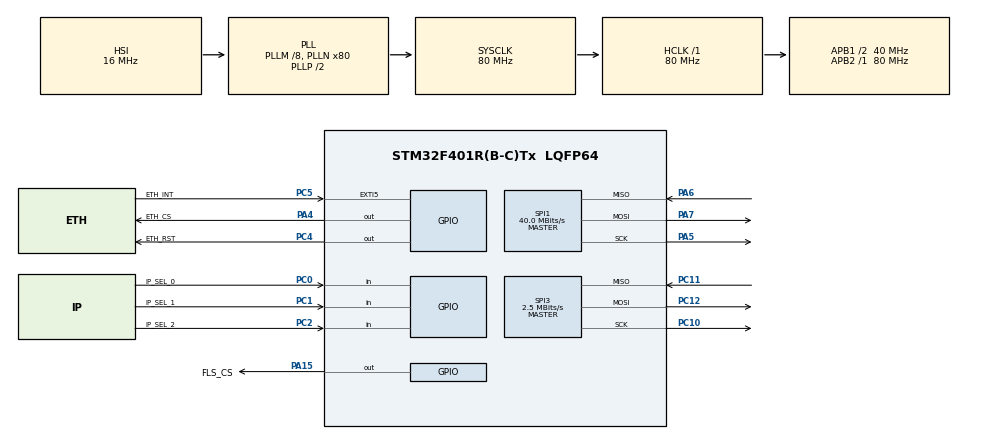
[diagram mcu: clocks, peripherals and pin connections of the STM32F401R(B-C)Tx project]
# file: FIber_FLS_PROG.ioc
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Mcu.Family=STM32F4
Mcu.Name=STM32F401R(B-C)Tx
Mcu.Package=LQFP64
NVIC.EXTI9_5_IRQn=true\:0\:0\:false\:false\:true\:true\:true\:true
NVIC.PriorityGroup=NVIC_PRIORITYGROUP_4
NVIC.SPI1_IRQn=true\:0\:0\:false\:false\:true\:true\:true\:true
NVIC.SPI3_IRQn=true\:0\:0\:false\:false\:true\:true\:true\:true
PA15.GPIO_Label=FLS_CS
PA15.GPIO_PuPd=GPIO_PULLUP
PA15.GPIO_Speed=GPIO_SPEED_FREQ_VERY_HIGH
PA15.PinState=GPIO_PIN_SET
PA15.Signal=GPIO_Output
PA4.GPIO_Label=ETH_CS
PA4.GPIO_ModeDefaultOutputPP=GPIO_MODE_OUTPUT_PP
PA4.GPIO_PuPd=GPIO_PULLUP
PA4.GPIO_Speed=GPIO_SPEED_FREQ_VERY_HIGH
PA4.PinState=GPIO_PIN_SET
PA4.Signal=GPIO_Output
PA5.Mode=Full_Duplex_Master
PA5.Signal=SPI1_SCK
PA6.Mode=Full_Duplex_Master
PA6.Signal=SPI1_MISO
PA7.Mode=Full_Duplex_Master
PA7.Signal=SPI1_MOSI
PC0.GPIO_Label=IP_SEL_0
PC0.Signal=GPIO_Input
PC1.GPIO_Label=IP_SEL_1
PC1.Signal=GPIO_Input
PC10.Mode=Full_Duplex_Master
PC10.Signal=SPI3_SCK
PC11.Mode=Full_Duplex_Master
PC11.Signal=SPI3_MISO
PC12.Mode=Full_Duplex_Master
PC12.Signal=SPI3_MOSI
PC2.GPIO_Label=IP_SEL_2
PC2.Signal=GPIO_Input
PC4.GPIO_Label=ETH_RST
PC4.GPIO_PuPd=GPIO_PULLUP
PC4.GPIO_Speed=GPIO_SPEED_FREQ_HIGH
PC4.PinState=GPIO_PIN_SET
PC4.Signal=GPIO_Output
PC5.GPIO_Label=ETH_INT
PC5.GPIO_PuPd=GPIO_PULLUP
PC5.Signal=GPXTI5
ProjectManager.HeapSize=0x200
ProjectManager.StackSize=0x400
ProjectManager.TargetToolchain=STM32CubeIDE
RCC.48MHZClocksFreq_Value=40000000
RCC.AHBFreq_Value=80000000
RCC.APB1CLKDivider=RCC_HCLK_DIV2
RCC.APB1Freq_Value=40000000
RCC.APB1TimFreq_Value=80000000
RCC.APB2Freq_Value=80000000
RCC.APB2TimFreq_Value=80000000
RCC.CortexFreq_Value=80000000
RCC.HCLKFreq_Value=80000000
RCC.HSE_VALUE=25000000
RCC.HSI_VALUE=16000000
RCC.LSE_VALUE=32768
RCC.PLLM=8
RCC.PLLN=80
RCC.SYSCLKFreq_VALUE=80000000
RCC.SYSCLKSource=RCC_SYSCLKSOURCE_PLLCLK
RCC.VCOOutputFreq_Value=160000000
SPI1.BaudRatePrescaler=SPI_BAUDRATEPRESCALER_2
SPI1.CalculateBaudRate=40.0 MBits/s
SPI1.Direction=SPI_DIRECTION_2LINES
SPI1.Mode=SPI_MODE_MASTER
SPI1.VirtualType=VM_MASTER
SPI3.BaudRatePrescaler=SPI_BAUDRATEPRESCALER_16
SPI3.CalculateBaudRate=2.5 MBits/s
SPI3.Direction=SPI_DIRECTION_2LINES
SPI3.Mode=SPI_MODE_MASTER
SPI3.VirtualType=VM_MASTER
board=custom

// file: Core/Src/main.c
/* USER CODE BEGIN Header */
/**
  ******************************************************************************
  * @file           : main.c
  * @brief          : Main program body
  ******************************************************************************
  * @attention
  *
  * Copyright (c) 2026 STMicroelectronics.
  * All rights reserved.
  *
  * This software is licensed under terms that can be found in the LICENSE file
  * in the root directory of this software component.
  * If no LICENSE file comes with this software, it is provided AS-IS.
  *
  ******************************************************************************
  */
/* USER CODE END Header */
#include "main.h"
#include "spi.h"
#include "gpio.h"

/* USER CODE BEGIN Includes */
#include "FLS/w25qxx.h"
#include "flash_wrapper/flash_wrapper.h"
#include "transport/transport.h"
#include "protocol/protocol.h"
/* USER CODE END Includes */

void SystemClock_Config(void);

int main(void)
{

  /* MCU Configuration--------------------------------------------------------*/

  /* Reset of all peripherals, Initializes the Flash interface and the Systick. */
  HAL_Init();

  /* Configure the system clock */
  SystemClock_Config();

  /* Initialize all configured peripherals */
  MX_GPIO_Init();
  MX_SPI1_Init();
  MX_SPI3_Init();
  /* USER CODE BEGIN 2 */
  FW_Init();
  Transport_Init();
  Protocol_Init();

  /* USER CODE END 2 */

  /* Infinite loop */
  while (1)
  {

    /* USER CODE BEGIN 3 */
    Protocol_Process();
  }
  /* USER CODE END 3 */
}

void SystemClock_Config(void)
{
  RCC_OscInitTypeDef RCC_OscInitStruct = {0};
  RCC_ClkInitTypeDef RCC_ClkInitStruct = {0};

  /** Configure the main internal regulator output voltage
  */
  __HAL_RCC_PWR_CLK_ENABLE();
  __HAL_PWR_VOLTAGESCALING_CONFIG(PWR_REGULATOR_VOLTAGE_SCALE2);

  /** Initializes the RCC Oscillators according to the specified parameters
  * in the RCC_OscInitTypeDef structure.
  */
  RCC_OscInitStruct.OscillatorType = RCC_OSCILLATORTYPE_HSI;
  RCC_OscInitStruct.HSIState = RCC_HSI_ON;
  RCC_OscInitStruct.HSICalibrationValue = RCC_HSICALIBRATION_DEFAULT;
  RCC_OscInitStruct.PLL.PLLState = RCC_PLL_ON;
  RCC_OscInitStruct.PLL.PLLSource = RCC_PLLSOURCE_HSI;
  RCC_OscInitStruct.PLL.PLLM = 8;
  RCC_OscInitStruct.PLL.PLLN = 80;
  RCC_OscInitStruct.PLL.PLLP = RCC_PLLP_DIV2;
  RCC_OscInitStruct.PLL.PLLQ = 4;
  if (HAL_RCC_OscConfig(&RCC_OscInitStruct) != HAL_OK)
  {
    Error_Handler();
  }

  /** Initializes the CPU, AHB and APB buses clocks
  */
  RCC_ClkInitStruct.ClockType = RCC_CLOCKTYPE_HCLK|RCC_CLOCKTYPE_SYSCLK
                              |RCC_CLOCKTYPE_PCLK1|RCC_CLOCKTYPE_PCLK2;
  RCC_ClkInitStruct.SYSCLKSource = RCC_SYSCLKSOURCE_PLLCLK;
  RCC_ClkInitStruct.AHBCLKDivider = RCC_SYSCLK_DIV1;
  RCC_ClkInitStruct.APB1CLKDivider = RCC_HCLK_DIV2;
  RCC_ClkInitStruct.APB2CLKDivider = RCC_HCLK_DIV1;

  if (HAL_RCC_ClockConfig(&RCC_ClkInitStruct, FLASH_LATENCY_2) != HAL_OK)
  {
    Error_Handler();
  }
}

void Error_Handler(void)
{
  __disable_irq();
  while (1)
  {
  }
}
